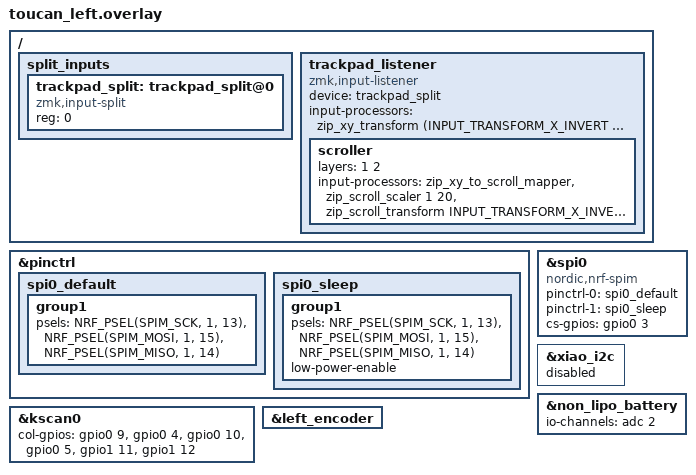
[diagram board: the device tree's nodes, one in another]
#include "toucan.dtsi"
#include <dt-bindings/zmk/input_transform.h>
#include <input/processors.dtsi>

&pinctrl {
    spi0_default: spi0_default {
        group1 {
            psels = <NRF_PSEL(SPIM_SCK, 1, 13)>,
                <NRF_PSEL(SPIM_MOSI, 1, 15)>,
                <NRF_PSEL(SPIM_MISO, 1, 14)>;
        };
    };
     spi0_sleep: spi0_sleep {
        group1 {
            psels = <NRF_PSEL(SPIM_SCK, 1, 13)>,
                    <NRF_PSEL(SPIM_MOSI, 1, 15)>,
                    <NRF_PSEL(SPIM_MISO, 1, 14)>;
            low-power-enable;
        };
    };
};

nice_view_spi: &spi0 {
   compatible = "nordic,nrf-spim";
   pinctrl-0 = <&spi0_default>;
   pinctrl-1 = <&spi0_sleep>;
   pinctrl-names = "default", "sleep";
   cs-gpios = <&gpio0 3 GPIO_ACTIVE_HIGH>;
};

&xiao_i2c {
    status = "disabled";
};

&kscan0 {
    col-gpios
    = <&gpio0 9 GPIO_ACTIVE_HIGH>
    , <&gpio0 4 GPIO_ACTIVE_HIGH>
    , <&gpio0 10 GPIO_ACTIVE_HIGH>
    , <&gpio0 5 GPIO_ACTIVE_HIGH>
    , <&gpio1 11 GPIO_ACTIVE_HIGH>
    , <&gpio1 12 GPIO_ACTIVE_HIGH>
    ;
};

&non_lipo_battery {
    io-channels = <&adc 2>;
};

&left_encoder {
    status = "okay";
};

/ {
    split_inputs {
        #address-cells = <1>;
        #size-cells = <0>;

        trackpad_split: trackpad_split@0 {
            compatible = "zmk,input-split";
            reg = <0>;
        };
    };

    trackpad_listener: trackpad_listener {
        compatible = "zmk,input-listener";
        status = "okay";
        device = <&trackpad_split>;
        input-processors = <&zip_xy_transform (INPUT_TRANSFORM_X_INVERT | INPUT_TRANSFORM_Y_INVERT)>;

        scroller {
            layers = <1 2>;
            input-processors = <
                &zip_xy_to_scroll_mapper
                &zip_scroll_scaler 1 20
                &zip_scroll_transform INPUT_TRANSFORM_X_INVERT
            >;
        };
    };
};
